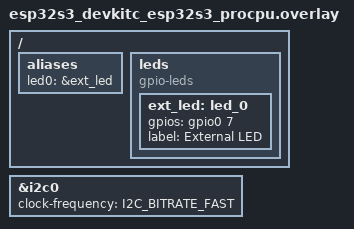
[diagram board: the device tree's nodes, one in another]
/*
 * ESPr Developer S3 Type-C 用の overlay
 * (Zephyr のボード名は esp32s3_devkitc/esp32s3/procpu を流用)
 *
 * SPDX-License-Identifier: Apache-2.0
 */

/ {
	aliases {
		led0 = &ext_led;
	};

	leds {
		compatible = "gpio-leds";
		ext_led: led_0 {
			gpios = <&gpio0 7 GPIO_ACTIVE_HIGH>;
			label = "External LED";
		};
	};
};

&i2c0 {
	status = "okay";
	clock-frequency = <I2C_BITRATE_FAST>;
};
